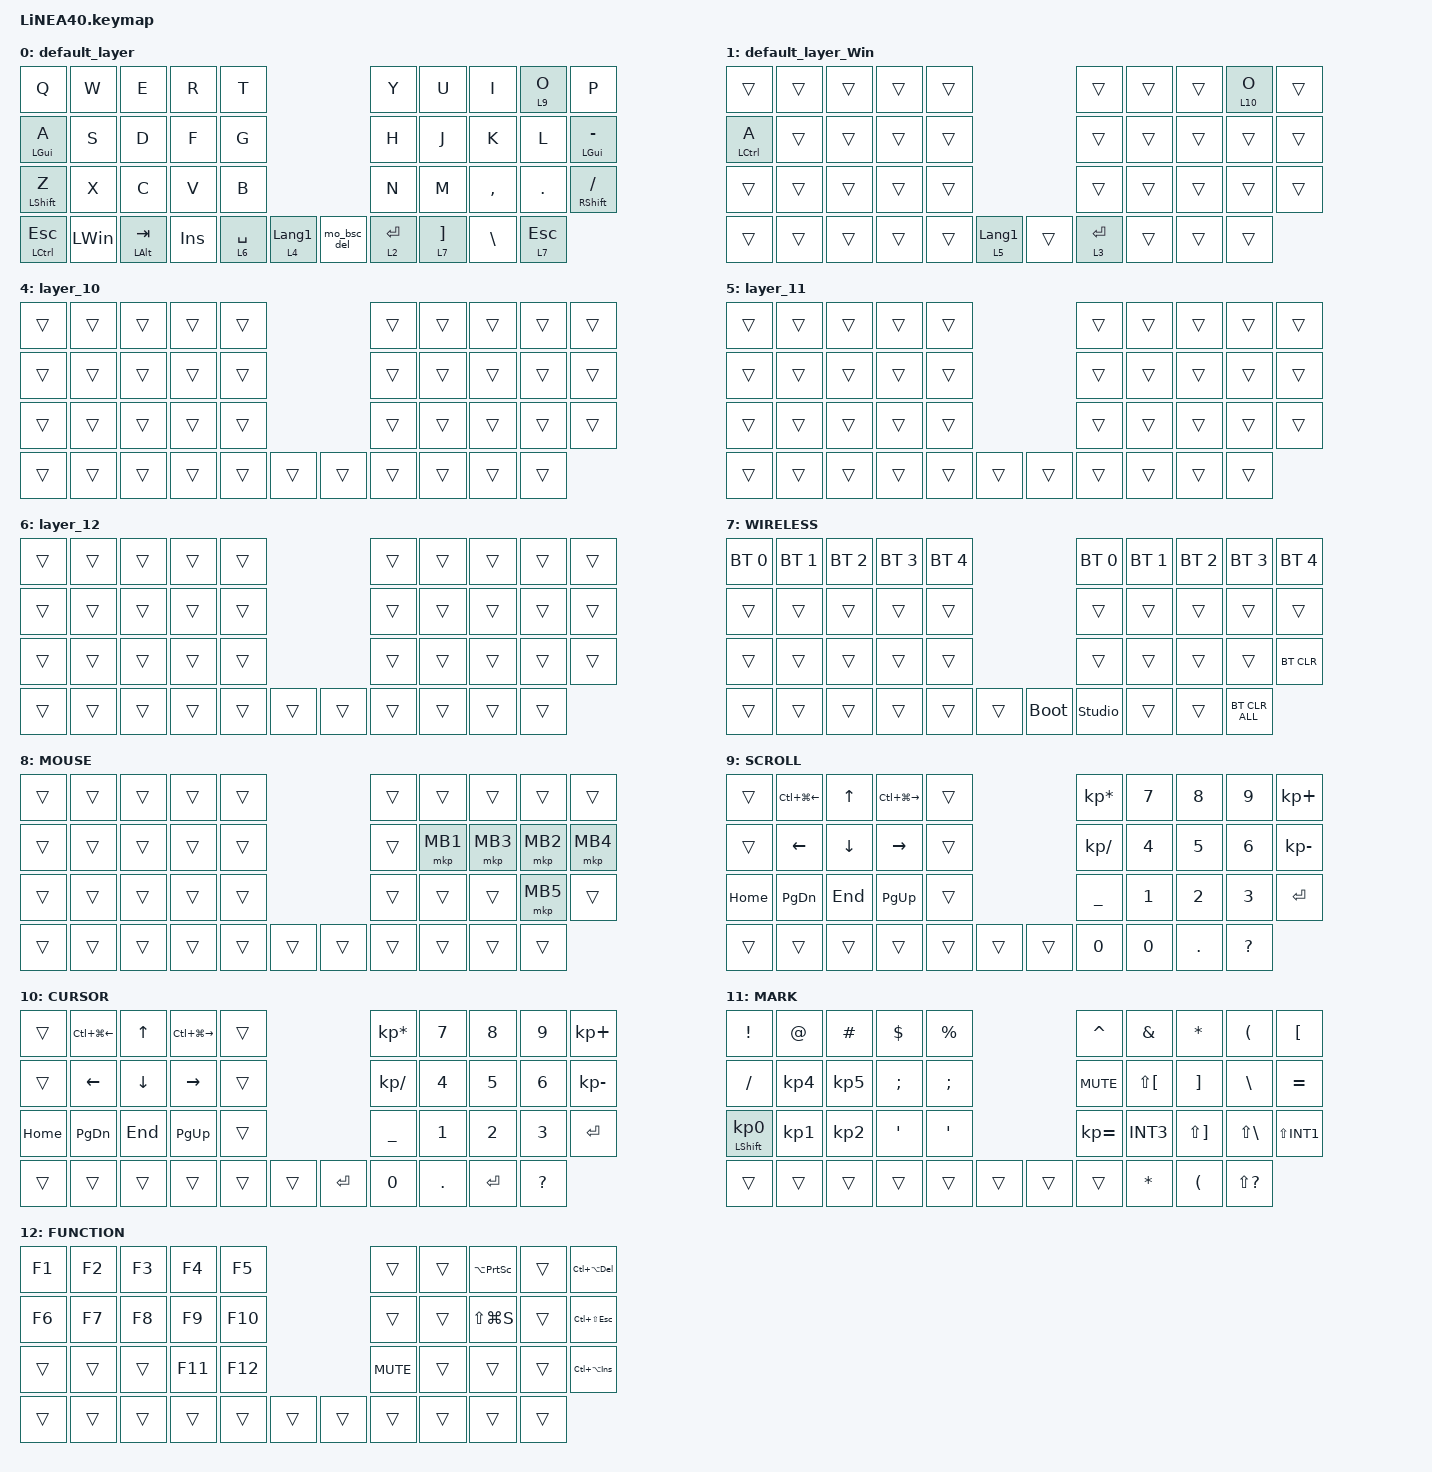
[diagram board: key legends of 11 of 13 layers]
#define ZMK_POINTING_DEFAULT_SCRL_VAL 150

#include <dt-bindings/zmk/input_transform.h>
#include <input/processors.dtsi>
#include <zephyr/dt-bindings/input/input-event-codes.h>
#include <behaviors.dtsi>
#include <dt-bindings/zmk/bt.h>
#include <dt-bindings/zmk/keys.h>
#include <dt-bindings/zmk/pointing.h>

#define MOUSE 1
#define MARK 2
#define CURSOR 3
#define FUNCTION 4
#define SCROLL 5
#define WIRELESS 6

//mouse cursol

&mmv {
    delay-ms = <20>;
    trigger-period-ms = <5>;
    time-to-max-speed-ms = <100>;
    acceleration-exponent = <2>;
};

//mouse scroll

&msc {
    delay-ms = <3>;
    trigger-period-ms = <3>;
    time-to-max-speed-ms = <100>;
    acceleration-exponent = <0>;
};

/ {
    input_processors {
        zip_wheel_scaler: zip_wheel_scaler {
            compatible = "zmk,input-processor-scaler";
            #input-processor-cells = <2>;
            type = <INPUT_EV_REL>;
            codes = <INPUT_REL_WHEEL>;
            track-remainders;
        };
    };
};

&msc_input_listener {
    speed_up {
        layers = <FUNCTION>;
        input-processors = <&zip_wheel_scaler 3 1>; //スクロールを3倍速にする
    };
};

&trackball_listener {
    scroller {
        layers = <SCROLL>;
        input-processors =
            <&zip_xy_transform INPUT_TRANSFORM_Y_INVERT>,
            //スクロール方向を逆転,,
            <&zip_xy_to_scroll_mapper>;
    };
};

/ {
    combos {
        compatible = "zmk,combos";

        ZenkakuHankaku {
            bindings = <&kp TAB>;
            key-positions = <11 12>;
        };

        DeleteKey {
            bindings = <&kp ESC>;
            key-positions = <1 2>;
        };

        InsertKey {
            bindings = <&kp INS>;
            key-positions = <6 7>;
        };

        CenterClick {
            bindings = <&mkp MB3>;
            key-positions = <17 16>;
        };

        RightClick {
            bindings = <&mkp MB2>;
            key-positions = <18 17>;
        };

        PrevClick {
            bindings = <&mkp MB4>;
            key-positions = <27 28>;
        };

        ClickNext {
            bindings = <&mkp MB5>;
            key-positions = <26 27>;
        };

        a {
            bindings = <&none>;
            key-positions = <17 18 19 16 28 26>;
        };

        f10 {
            bindings = <&kp F10>;
            key-positions = <22 23>;
        };

        tab2 {
            bindings = <&kp TAB>;
            key-positions = <17 18>;
        };

        Spotlight {
            bindings = <&kp LG(SPACE)>;
            key-positions = <7 8>;
            layers = <0>;
        };

        search {
            bindings = <&kp LEFT_GUI>;
            key-positions = <7 8>;
            layers = <1>;
        };

        missioncontrol {
            bindings = <&none>;
            key-positions = <7 8>;
            layers = <2>;
        };

        Windows_tab {
            bindings = <&none>;
            key-positions = <7 8>;
            layers = <3>;
        };
    };

    behaviors {
        re_kp: sensor_rotate_kp {
            compatible = "zmk,behavior-sensor-rotate-var";
            #sensor-binding-cells = <2>;
            bindings = <&kp>, <&kp>;
        };

        mouse_scrl: mouse_wheel_scrl {
            compatible = "zmk,behavior-sensor-rotate-var";
            #sensor-binding-cells = <2>;
            bindings = <&msc>, <&msc>;

            tap-ms = <20>;
        };

        // 「マック・スワッパー」の定義

        mac_swapper: mac_swapper {
            compatible = "zmk,behavior-smart-toggle";
            #binding-cells = <0>;
            bindings = <&kp LGUI>, <&kp TAB>;

            // 1つ目がホールド(Cmd)、2つ目が連打用(Tab)
            // ignored-key-positions = <8>;     // 隣のキー（逆送り用）を指定。※環境に合わせて番号を調整してください
        };

        win_swapper: win_swapper {
            compatible = "zmk,behavior-smart-toggle";
            #binding-cells = <0>;
            bindings = <&kp LALT>, <&kp TAB>;

            // ignored-key-positions = <8>;
        };

        mo_bsc_del: mo_bsc_del {
            compatible = "zmk,behavior-mod-morph";
            label = "MO_BSC_DEL";
            bindings = <&kp BACKSPACE>, <&kp DELETE>;

            #binding-cells = <0>;
            mods = <(MOD_LSFT|MOD_RSFT)>;
        };
    };

    keymap {
        compatible = "zmk,keymap";

        default_layer {
            bindings = <
&kp Q           &kp W         &kp E             &kp R    &kp T                                         &kp Y        &kp U  &kp I                &lt 9 O        &kp P
&mt LEFT_GUI A  &kp S         &kp D             &kp F    &kp G                                         &kp H        &kp J  &kp K                &kp L          &mt LEFT_GUI MINUS
&mt LSHFT Z     &kp X         &kp C             &kp V    &kp B                                         &kp N        &kp M  &kp COMMA            &kp DOT        &mt RIGHT_SHIFT SLASH
&mt LCTRL ESC   &kp LEFT_WIN  &mt LEFT_ALT TAB  &kp INS  &lt 6 SPACE  &lt 4 LANGUAGE_1    &mo_bsc_del  &lt 2 ENTER         &lt 7 RIGHT_BRACKET  &kp BACKSLASH  &lt 7 ESC
            >;

            sensor-bindings = <&mouse_scrl SCRL_DOWN SCRL_UP>;
        };

        default_layer_Win {
            bindings = <
&trans       &trans  &trans  &trans  &trans                              &trans       &trans  &trans  &lt 10 O  &trans
&mt LCTRL A  &trans  &trans  &trans  &trans                              &trans       &trans  &trans  &trans    &trans
&trans       &trans  &trans  &trans  &trans                              &trans       &trans  &trans  &trans    &trans
&trans       &trans  &trans  &trans  &trans  &lt 5 LANGUAGE_1    &trans  &lt 3 ENTER          &trans  &trans    &trans
            >;
        };

        ARROW {
            bindings = <
&kp PG_UP          &kp PG_DN      &trans  &trans  &kp LC(UP_ARROW)                              &kp LG(Q)  &kp LC(LEFT_ARROW)  &kp UP_ARROW    &kp LC(RIGHT_ARROW)  &mac_swapper
&trans             &trans         &trans  &trans  &kp LC(DOWN_ARROW)                            &trans     &kp LEFT_ARROW      &kp DOWN_ARROW  &kp RIGHT_ARROW      &trans
&mt (LSHFT) LG(Z)  &kp LG(LS(Z))  &trans  &trans  &kp LG(Q)                                     &trans     &kp LC(LS(TAB))     &kp LG(W)       &kp LC(TAB)          &kp LG(Q)
&trans             &trans         &trans  &trans  &kp LG(BACKSPACE)   &kp LANGUAGE_2    &trans  &trans                         &trans          &trans               &trans
            >;
        };

        ARROW_Win {
            bindings = <
&kp PG_UP          &kp PG_DN  &trans  &trans  &kp LG(TAB)                            &trans  &trans          &kp UP_ARROW    &trans           &win_swapper
&trans             &trans     &trans  &trans  &kp LG(D)                              &trans  &kp LEFT_ARROW  &kp DOWN_ARROW  &kp RIGHT_ARROW  &trans
&mt (LSHFT) LC(Z)  &kp LC(Y)  &trans  &trans  &trans                                 &trans  &trans          &trans          &trans           &trans
&trans             &trans     &trans  &trans  &trans       &kp LANGUAGE_2    &trans  &trans                  &trans          &trans           &trans
            >;
        };

        layer_10 {
            bindings = <
&trans  &trans  &trans  &trans  &trans                    &trans  &trans  &trans  &trans  &trans
&trans  &trans  &trans  &trans  &trans                    &trans  &trans  &trans  &trans  &trans
&trans  &trans  &trans  &trans  &trans                    &trans  &trans  &trans  &trans  &trans
&trans  &trans  &trans  &trans  &trans  &trans    &trans  &trans          &trans  &trans  &trans
            >;
        };

        layer_11 {
            bindings = <
&trans  &trans  &trans  &trans  &trans                    &trans  &trans  &trans  &trans  &trans
&trans  &trans  &trans  &trans  &trans                    &trans  &trans  &trans  &trans  &trans
&trans  &trans  &trans  &trans  &trans                    &trans  &trans  &trans  &trans  &trans
&trans  &trans  &trans  &trans  &trans  &trans    &trans  &trans          &trans  &trans  &trans
            >;
        };

        layer_12 {
            bindings = <
&trans  &trans  &trans  &trans  &trans                    &trans  &trans  &trans  &trans  &trans
&trans  &trans  &trans  &trans  &trans                    &trans  &trans  &trans  &trans  &trans
&trans  &trans  &trans  &trans  &trans                    &trans  &trans  &trans  &trans  &trans
&trans  &trans  &trans  &trans  &trans  &trans    &trans  &trans          &trans  &trans  &trans
            >;
        };

        WIRELESS {
            bindings = <
&bt BT_SEL 0  &bt BT_SEL 1  &bt BT_SEL 2  &bt BT_SEL 3  &bt BT_SEL 4                         &bt BT_SEL 0    &bt BT_SEL 1  &bt BT_SEL 2  &bt BT_SEL 3  &bt BT_SEL 4
&trans        &trans        &trans        &trans        &trans                               &trans          &trans        &trans        &trans        &trans
&trans        &trans        &trans        &trans        &trans                               &trans          &trans        &trans        &trans        &bt BT_CLR
&trans        &trans        &trans        &trans        &trans        &trans    &bootloader  &studio_unlock                &trans        &trans        &bt BT_CLR_ALL
            >;

            sensor-bindings = <&inc_dec_kp RIGHT_ARROW LEFT_ARROW>;
        };

        MOUSE {
            bindings = <
&trans  &trans  &trans  &trans  &trans                    &trans  &trans    &trans    &trans    &trans
&trans  &trans  &trans  &trans  &trans                    &trans  &mkp MB1  &mkp MB3  &mkp MB2  &mkp MB4
&trans  &trans  &trans  &trans  &trans                    &trans  &trans    &trans    &mkp MB5  &trans
&trans  &trans  &trans  &trans  &trans  &trans    &trans  &trans            &trans    &trans    &trans
            >;
        };

        SCROLL {
            bindings = <
&trans    &kp LC(LG(LEFT_ARROW))  &kp UP_ARROW  &kp LC(LG(RIGHT_ARROW))  &trans                    &kp KP_MULTIPLY  &kp NUMBER_7  &kp NUMBER_8  &kp NUMBER_9  &kp KP_PLUS
&trans    &kp LEFT_ARROW          &kp DOWN      &kp RIGHT_ARROW          &trans                    &kp KP_SLASH     &kp NUMBER_4  &kp NUMBER_5  &kp NUMBER_6  &kp KP_MINUS
&kp HOME  &kp PAGE_DOWN           &kp END       &kp PAGE_UP              &trans                    &kp UNDER        &kp NUMBER_1  &kp NUMBER_2  &kp NUMBER_3  &kp ENTER
&trans    &trans                  &trans        &trans                   &trans  &trans    &trans  &kp NUMBER_0                   &kp NUMBER_0  &kp DOT       &kp QUESTION
            >;

            sensor-bindings = <&inc_dec_kp DOWN_ARROW UP_ARROW>;
        };

        CURSOR {
            bindings = <
&trans    &kp LC(LG(LEFT_ARROW))  &kp UP_ARROW  &kp LC(LG(RIGHT_ARROW))  &trans                       &kp KP_MULTIPLY  &kp NUMBER_7  &kp NUMBER_8  &kp NUMBER_9  &kp KP_PLUS
&trans    &kp LEFT_ARROW          &kp DOWN      &kp RIGHT_ARROW          &trans                       &kp KP_SLASH     &kp NUMBER_4  &kp NUMBER_5  &kp NUMBER_6  &kp KP_MINUS
&kp HOME  &kp PAGE_DOWN           &kp END       &kp PAGE_UP              &trans                       &kp UNDER        &kp NUMBER_1  &kp NUMBER_2  &kp NUMBER_3  &kp ENTER
&trans    &trans                  &trans        &trans                   &trans  &trans    &kp ENTER  &kp NUMBER_0                   &kp DOT       &kp ENTER     &kp QUESTION
            >;
        };

        MARK {
            bindings = <
&kp EXCLAMATION             &kp AT           &kp HASH         &kp DOLLAR     &kp PERCENT                      &kp CARET     &kp AMPERSAND  &kp ASTERISK           &kp LEFT_PARENTHESIS  &kp LBKT
&kp SLASH                   &kp KP_NUMBER_4  &kp KP_NUMBER_5  &kp SEMICOLON  &kp SEMICOLON                    &kp C_MUTE    &kp LS(LBKT)   &kp RIGHT_BRACKET      &kp BACKSLASH         &kp EQUAL
&mt LEFT_SHIFT KP_NUMBER_0  &kp KP_NUMBER_1  &kp KP_NUMBER_2  &kp APOS       &kp SQT                          &kp KP_EQUAL  &kp INT3       &kp LS(RIGHT_BRACKET)  &kp LS(BACKSLASH)     &kp LS(INT1)
&trans                      &trans           &trans           &trans         &trans         &trans    &trans  &trans                       &kp ASTERISK           &kp LEFT_PARENTHESIS  &kp LS(QUESTION)
            >;

            sensor-bindings = <&re_kp C_VOLUME_DOWN C_VOLUME_UP>;
        };

        FUNCTION {
            bindings = <
&kp F1  &kp F2  &kp F3  &kp F4   &kp F5                     &trans      &trans  &kp LA(PRINTSCREEN)  &trans  &kp LC(LA(DELETE))
&kp F6  &kp F7  &kp F8  &kp F9   &kp F10                    &trans      &trans  &kp LS(LG(S))        &trans  &kp LC(LS(ESCAPE))
&trans  &trans  &trans  &kp F11  &kp F12                    &kp C_MUTE  &trans  &trans               &trans  &kp LC(LA(INS))
&trans  &trans  &trans  &trans   &trans   &trans    &trans  &trans              &trans               &trans  &trans
            >;

            sensor-bindings = <&mouse_scrl SCRL_DOWN SCRL_UP>;
        };
    };
};
